# ATSAMA5D28CLD2G register map
Vendor: Microchip Technology; Series: SAMA5D2; File version: 0
Registers are 32-bit, read-write, reset 0x0 unless marked. A register's access mark holds for its fields unless they carry their own. Offsets are from the block's base; [hi:lo] are bit positions; lines under a group give offsets from that group; {n}, {i} and the like mark numbered series.

## HSMC — Static Memory Controller
Base 0xF8014000; register names take the prefix SMC_
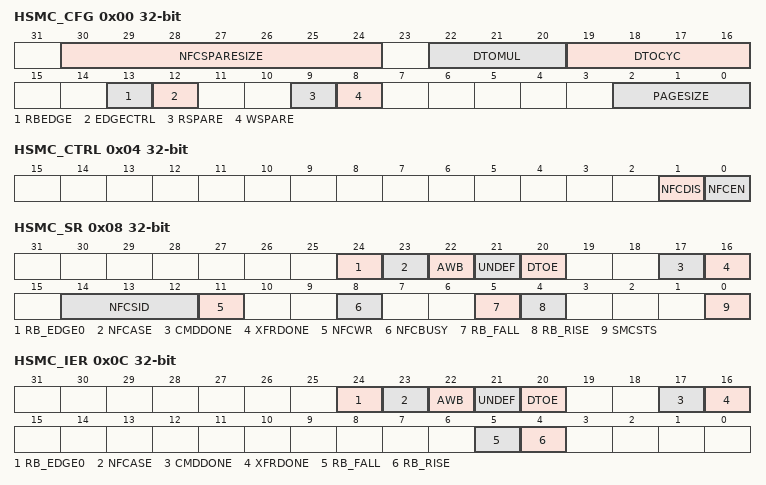
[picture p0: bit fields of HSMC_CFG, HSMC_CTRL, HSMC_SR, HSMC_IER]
0x00 HSMC_CFG — NFC Configuration Register
  [30:24] NFCSPARESIZE — NAND Flash Spare Area Size Retrieved by the Host Controller
  [22:20] DTOMUL — Data Timeout Multiplier
    0=DTOCYC; 1=X16 (DTOCYC x 16); 2=X128 (DTOCYC x 128); 3=X256 (DTOCYC x 256); 4=X1024 (DTOCYC x 1024); 5=X4096 (DTOCYC x 4096); 6=X65536 (DTOCYC x 65536); 7=X1048576 (DTOCYC x 1048576)
  [19:16] DTOCYC — Data Timeout Cycle Number
  [13] RBEDGE — Ready/Busy Signal Edge Detection
  [12] EDGECTRL — Rising/Falling Edge Detection Control
  [9] RSPARE — Read Spare Area
  [8] WSPARE — Write Spare Area
  [2:0] PAGESIZE — Page Size of the NAND Flash Device
    0=PS512 (Main area 512 bytes); 1=PS1024 (Main area 1024 bytes); 2=PS2048 (Main area 2048 bytes); 3=PS4096 (Main area 4096 bytes); 4=PS8192 (Main area 8192 bytes)
0x04 HSMC_CTRL wo — NFC Control Register
  [1] NFCDIS — NAND Flash Controller Disable
  [0] NFCEN — NAND Flash Controller Enable
0x08 HSMC_SR ro — NFC Status Register
  [24] RB_EDGE0 — Ready/Busy Line 0 Edge Detected
  [23] NFCASE — NFC Access Size Error
  [22] AWB — Accessing While Busy
  [21] UNDEF — Undefined Area Error
  [20] DTOE — Data Timeout Error
  [17] CMDDONE — Command Done
  [16] XFRDONE — NFC Data Transfer Terminated
  [14:12] NFCSID — NFC Chip Select ID (this field cannot be reset)
  [11] NFCWR — NFC Write/Read Operation (this field cannot be reset)
  [8] NFCBUSY — NFC Busy (this field cannot be reset)
  [5] RB_FALL — Selected Ready Busy Falling Edge Detected
  [4] RB_RISE — Selected Ready Busy Rising Edge Detected
  [0] SMCSTS — NAND Flash Controller Status (this field cannot be reset)
0x0C HSMC_IER wo — NFC Interrupt Enable Register
  [24] RB_EDGE0 — Ready/Busy Line 0 Interrupt Enable
  [23] NFCASE — NFC Access Size Error Interrupt Enable
  [22] AWB — Accessing While Busy Interrupt Enable
  [21] UNDEF — Undefined Area Access Interrupt Enable
  [20] DTOE — Data Timeout Error Interrupt Enable
  [17] CMDDONE — Command Done Interrupt Enable
  [16] XFRDONE — Transfer Done Interrupt Enable
  [5] RB_FALL — Ready Busy Falling Edge Detection Interrupt Enable
  [4] RB_RISE — Ready Busy Rising Edge Detection Interrupt Enable
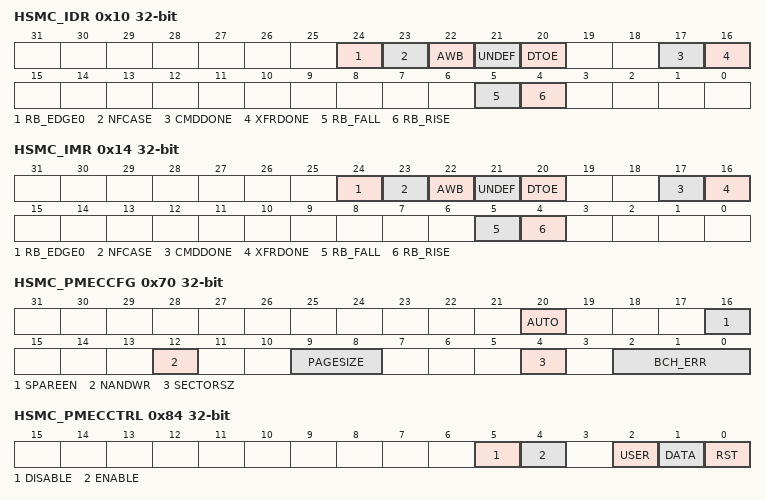
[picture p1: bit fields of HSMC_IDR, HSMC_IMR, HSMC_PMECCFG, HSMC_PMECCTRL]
0x10 HSMC_IDR wo — NFC Interrupt Disable Register
  [24] RB_EDGE0 — Ready/Busy Line 0 Interrupt Disable
  [23] NFCASE — NFC Access Size Error Interrupt Disable
  [22] AWB — Accessing While Busy Interrupt Disable
  [21] UNDEF — Undefined Area Access Interrupt Disable
  [20] DTOE — Data Timeout Error Interrupt Disable
  [17] CMDDONE — Command Done Interrupt Disable
  [16] XFRDONE — Transfer Done Interrupt Disable
  [5] RB_FALL — Ready Busy Falling Edge Detection Interrupt Disable
  [4] RB_RISE — Ready Busy Rising Edge Detection Interrupt Disable
0x14 HSMC_IMR ro — NFC Interrupt Mask Register
  [24] RB_EDGE0 — Ready/Busy Line 0 Interrupt Mask
  [23] NFCASE — NFC Access Size Error Interrupt Mask
  [22] AWB — Accessing While Busy Interrupt Mask
  [21] UNDEF — Undefined Area Access Interrupt Mask5
  [20] DTOE — Data Timeout Error Interrupt Mask
  [17] CMDDONE — Command Done Interrupt Mask
  [16] XFRDONE — Transfer Done Interrupt Mask
  [5] RB_FALL — Ready Busy Falling Edge Detection Interrupt Mask
  [4] RB_RISE — Ready Busy Rising Edge Detection Interrupt Mask
0x18 HSMC_ADDR — NFC Address Cycle Zero Register
  [7:0] ADDR_CYCLE0 — NAND Flash Array Address Cycle 0
0x1C HSMC_BANK — Bank Address Register
  [0] BANK — Bank Identifier
0x70 HSMC_PMECCFG — PMECC Configuration Register
  [20] AUTO — Automatic Mode Enable
  [16] SPAREEN — Spare Enable
  [12] NANDWR — NAND Write Access
  [9:8] PAGESIZE — Number of Sectors in the Page
    0=PAGESIZE_1SEC (1 sector for main area (512 or 1024 bytes)); 1=PAGESIZE_2SEC (2 sectors for main area (1024 or 2048 bytes)); 2=PAGESIZE_4SEC (4 sectors for main area (2048 or 4096 bytes)); 3=PAGESIZE_8SEC (8 sectors for main area (4096 or 8192 bytes))
  [4] SECTORSZ — Sector Size
    0=Use 512 Byte Sector in ECC Computation; 1=Use 1024 Byte Sector in ECC Computation
  [2:0] BCH_ERR — Error Correcting Capability
    0=2 errors; 1=4 errors; 2=8 errors; 3=12 errors; 4=24 errors; 5=32 errors
0x74 HSMC_PMECCSAREA — PMECC Spare Area Size Register
  [8:0] SPARESIZE — Spare Area Size
0x78 HSMC_PMECCSADDR — PMECC Start Address Register
  [8:0] STARTADDR — ECC Area Start Address
0x7C HSMC_PMECCEADDR — PMECC End Address Register
  [8:0] ENDADDR — ECC Area End Address
0x84 HSMC_PMECCTRL wo — PMECC Control Register
  [5] DISABLE — PMECC Enable
  [4] ENABLE — PMECC Enable
  [2] USER — Start a User Mode Phase
  [1] DATA — Start a Data Phase
  [0] RST — Reset the PMECC Module
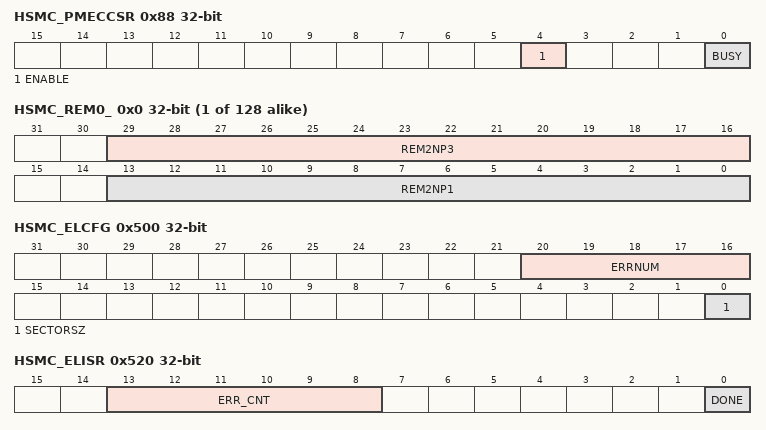
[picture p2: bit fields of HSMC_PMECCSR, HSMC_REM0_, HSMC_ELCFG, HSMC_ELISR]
0x88 HSMC_PMECCSR ro — PMECC Status Register
  [4] ENABLE — PMECC Enable bit
  [0] BUSY — The kernel of the PMECC is busy
0x8C HSMC_PMECCIER wo — PMECC Interrupt Enable register
  [0] ERRIE — Error Interrupt Enable
0x90 HSMC_PMECCIDR wo — PMECC Interrupt Disable Register
  [0] ERRID — Error Interrupt Disable
0x94 HSMC_PMECCIMR ro — PMECC Interrupt Mask Register
  [0] ERRIM — Error Interrupt Mask
0x98 HSMC_PMECCISR ro — PMECC Interrupt Status Register
  [7:0] ERRIS — Error Interrupt Status Register
{0xB0+0x40*i} SMC_PMECC[{i}] (i=0..7) group
  {0x0+4j} HSMC_PMECC[{j}] (j=0..13) ro — PMECC Redundancy 0 Register (sec_num = 0)
    [31:0] ECC — BCH Redundancy
{0x2B0+0x40*i} SMC_REM[{i}] (i=0..7) group
  {0x0+4j} HSMC_REM{j}_ ro (j=0..15) — PMECC Remainder {j} Register (sec_num = 0)
    [29:16] REM2NP3 — BCH Remainder 2 * N + 3
    [13:0] REM2NP1 — BCH Remainder 2 * N + 1
0x500 HSMC_ELCFG — PMECC Error Location Configuration Register
  [20:16] ERRNUM — Number of Errors
  [0] SECTORSZ — Sector Size
    0=Use 512 Byte Sector in Location Computation; 1=Use 1024 Byte Sector in Location Computation
0x504 HSMC_ELPRIM ro — PMECC Error Location Primitive Register
  [15:0] PRIMITIV — Primitive Polynomial
0x508 HSMC_ELEN wo — PMECC Error Location Enable Register
  [13:0] ENINIT — Error Location Enable
0x50C HSMC_ELDIS wo — PMECC Error Location Disable Register
  [0] DIS — Disable Error Location Engine
0x510 HSMC_ELSR ro — PMECC Error Location Status Register
  [0] BUSY — Error Location Engine Busy
0x514 HSMC_ELIER wo — PMECC Error Location Interrupt Enable register
  [0] DONE — Computation Terminated Interrupt Enable
0x518 HSMC_ELIDR wo — PMECC Error Location Interrupt Disable Register
  [0] DONE — Computation Terminated Interrupt Disable
0x51C HSMC_ELIMR ro — PMECC Error Location Interrupt Mask Register
  [0] DONE — Computation Terminated Interrupt Mask
0x520 HSMC_ELISR ro — PMECC Error Location Interrupt Status Register
  [13:8] ERR_CNT — Error Counter value
  [0] DONE — Computation Terminated Interrupt Status
0x528 HSMC_SIGMA0 ro — PMECC Error Location SIGMA 0 Register
  [13:0] SIGMA0 — Coefficient of degree 0 in the SIGMA polynomial
{0x528+4i} HSMC_SIGMA{i} (i=1..32) — PMECC Error Location SIGMA {i} Register
  [13:0] SIGMA{i} — Coefficient of degree x in the SIGMA polynomial
{0x5AC+4i} HSMC_ERRLOC[{i}] (i=0..31) ro — PMECC Error Location 0 Register
  [13:0] ERRLOCN — Error Position within the Set {sector area, spare area}
{0x700+0x14*i} SMC_CS_NUMBER[{i}] (i=0..3) group
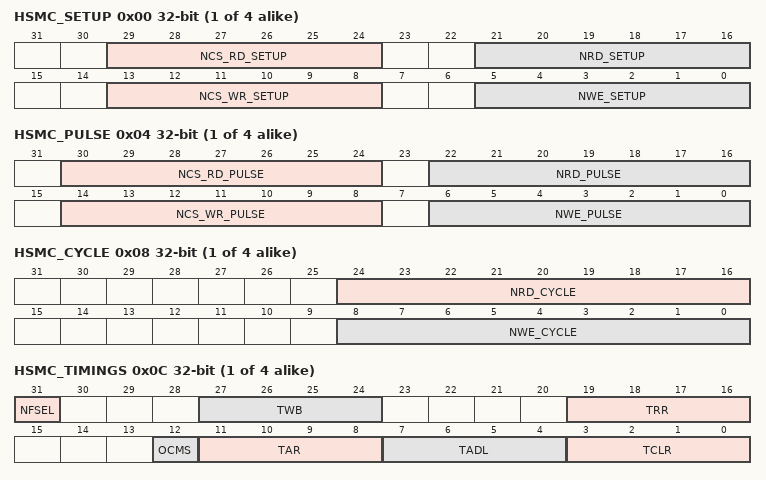
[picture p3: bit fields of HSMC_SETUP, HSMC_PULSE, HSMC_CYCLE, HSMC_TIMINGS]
  0x00 HSMC_SETUP — Setup Register
    [29:24] NCS_RD_SETUP — NCS Setup Length in Read Access
    [21:16] NRD_SETUP — NRD Setup Length
    [13:8] NCS_WR_SETUP — NCS Setup Length in Write Access
    [5:0] NWE_SETUP — NWE Setup Length
  0x04 HSMC_PULSE — Pulse Register
    [30:24] NCS_RD_PULSE — NCS Pulse Length in READ Access
    [22:16] NRD_PULSE — NRD Pulse Length
    [14:8] NCS_WR_PULSE — NCS Pulse Length in WRITE Access
    [6:0] NWE_PULSE — NWE Pulse Length
  0x08 HSMC_CYCLE — Cycle Register
    [24:16] NRD_CYCLE — Total Read Cycle Length
    [8:0] NWE_CYCLE — Total Write Cycle Length
  0x0C HSMC_TIMINGS — Timings Register
    [31] NFSEL — NAND Flash Selection
    [27:24] TWB — WEN High to REN to Busy
    [19:16] TRR — Ready to REN Low Delay
    [12] OCMS — Off Chip Memory Scrambling Enable
    [11:8] TAR — ALE to REN Low Delay
    [7:4] TADL — ALE to Data Start
    [3:0] TCLR — CLE to REN Low Delay
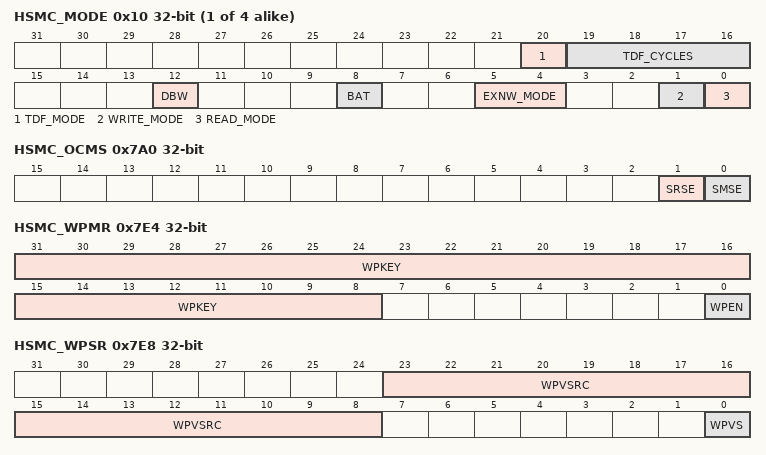
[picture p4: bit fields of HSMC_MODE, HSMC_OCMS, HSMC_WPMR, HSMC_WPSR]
  0x10 HSMC_MODE — Mode Register
    [20] TDF_MODE — TDF Optimization
    [19:16] TDF_CYCLES — Data Float Time
    [12] DBW — Data Bus Width
      0=BIT_8 (8-bit bus); 1=BIT_16 (16-bit bus)
    [8] BAT — Byte Access Type
      0=BYTE_SELECT (Byte select access type:- Write operation is controlled using NCS, NWE, NBS0, NBS1.- Read operation is controlled using NCS, NRD, NBS0, NBS1.); 1=BYTE_WRITE (Byte write access type:- Write operation is controlled using NCS, NWR0, NWR1.- Read operation is controlled using NCS and NRD.)
    [5:4] EXNW_MODE — NWAIT Mode
      0=DISABLED (Disabled-The NWAIT input signal is ignored on the corresponding Chip Select.); 2=FROZEN (Frozen Mode-If asserted, the NWAIT signal freezes the current read or write cycle. After deassertion, the read/write cycle is resumed from the point where it was stopped.); 3=READY (Ready Mode-The NWAIT signal indicates the availability of the external device at the end of the pulse of the controlling read or write signal, to complete the access. If high, the access normally completes. If low, the access is extended until NWAIT returns high.)
    [1] WRITE_MODE — Selection of the Control Signal for Write Operation
      0=NCS_CTRL (The Write operation is controller by the NCS signal.); 1=NWE_CTRL (The Write operation is controlled by the NWE signal)
    [0] READ_MODE — Selection of the Control Signal for Read Operation
      0=NCS_CTRL (The Read operation is controlled by the NCS signal.); 1=NRD_CTRL (The Read operation is controlled by the NRD signal.)
0x7A0 HSMC_OCMS — Off Chip Memory Scrambling Register
  [1] SRSE — NFC Internal SRAM Scrambling Enable
  [0] SMSE — Static Memory Controller Scrambling Enable
0x7A4 HSMC_KEY1 wo — Off Chip Memory Scrambling KEY1 Register
  [31:0] KEY1 — Off Chip Memory Scrambling (OCMS) Key Part 1
0x7A8 HSMC_KEY2 wo — Off Chip Memory Scrambling KEY2 Register
  [31:0] KEY2 — Off Chip Memory Scrambling (OCMS) Key Part 2
0x7E4 HSMC_WPMR — Write Protection Mode Register
  [31:8] WPKEY — Write Protection Key
    0x534D43=PASSWD (Writing any other value in this field aborts the write operation of bit WPEN.Always reads as 0.)
  [0] WPEN — Write Protection Enable
0x7E8 HSMC_WPSR ro — Write Protection Status Register
  [23:8] WPVSRC — Write Protection Violation Source
  [0] WPVS — Write Protection Violation Status
